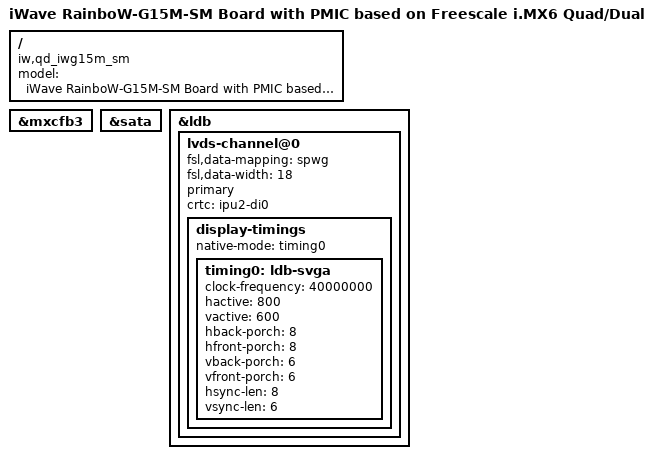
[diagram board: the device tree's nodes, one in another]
/*
 * Copyright (c) 2017 iWave Systems Technologies Pvt. Ltd.
 *
 * The code contained herein is licensed under the GNU General Public
 * License. You may obtain a copy of the GNU General Public License
 * Version 2 or later at the following locations:
 *
 * http://www.opensource.org/licenses/gpl-license.html
 * http://www.gnu.org/copyleft/gpl.html
 */

/dts-v1/;

#include "imx6q.dtsi"
#include "imx6qdl-iwg15m-sm.dtsi"

/ {
	model = "iWave RainboW-G15M-SM Board with PMIC based on Freescale i.MX6 Quad/Dual";
	compatible = "iw,qd_iwg15m_sm", "fsl,imx6q";
};

&mxcfb3 {
	status = "okay";
};

&sata {
	status = "okay";
};

&ldb {
	status = "okay";

	lvds-channel@0 {
		fsl,data-mapping = "spwg";
		fsl,data-width = <18>;
		primary;
		crtc = "ipu2-di0";
		status = "okay";

		display-timings {
			native-mode = <&timing0>;
			timing0: ldb-svga {
				clock-frequency = <40000000>;
				hactive = <800>;
				vactive = <600>;
				hback-porch = <8>;
				hfront-porch = <8>;
				vback-porch = <6>;
				vfront-porch = <6>;
				hsync-len = <8>;
				vsync-len = <6>;
			};
		};
	};
};
